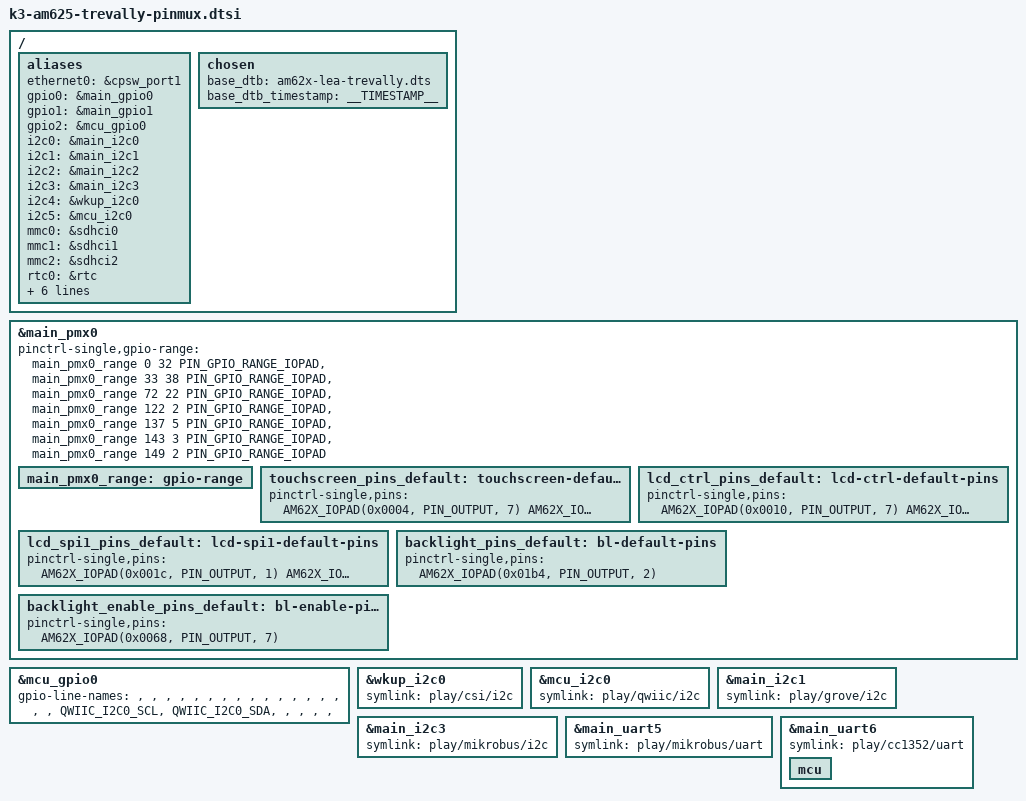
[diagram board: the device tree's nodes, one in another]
// SPDX-License-Identifier: GPL-2.0-only OR MIT

#include <dt-bindings/gpio/gpio.h>

/ {
	/* rtc1 = &wkup_rtc0; diff */
	aliases {
		ethernet0 = &cpsw_port1;
		gpio0 = &main_gpio0;
		gpio1 = &main_gpio1;
		gpio2 = &mcu_gpio0;
		i2c0 = &main_i2c0;
		i2c1 = &main_i2c1;
		i2c2 = &main_i2c2;
		i2c3 = &main_i2c3;
		i2c4 = &wkup_i2c0;
		i2c5 = &mcu_i2c0;
		mmc0 = &sdhci0;
		mmc1 = &sdhci1;
		mmc2 = &sdhci2;
		rtc0 = &rtc;
		rtc1 = &wkup_rtc0;
		serial0 = &main_uart5;
		serial1 = &main_uart6;
		serial2 = &main_uart0;
		usb0 = &usb0;
		usb1 = &usb1;
	};

	chosen {
		base_dtb = "am62x-lea-trevally.dts";
		base_dtb_timestamp = __TIMESTAMP__;
	};

};

&main_pmx0 {
	pinctrl-single,gpio-range =
		<&main_pmx0_range 0 32 PIN_GPIO_RANGE_IOPAD>,
		<&main_pmx0_range 33 38 PIN_GPIO_RANGE_IOPAD>,
		<&main_pmx0_range 72 22 PIN_GPIO_RANGE_IOPAD>,
		<&main_pmx0_range 122 2 PIN_GPIO_RANGE_IOPAD>,
		<&main_pmx0_range 137 5 PIN_GPIO_RANGE_IOPAD>,
		<&main_pmx0_range 143 3 PIN_GPIO_RANGE_IOPAD>,
		<&main_pmx0_range 149 2 PIN_GPIO_RANGE_IOPAD>;

	main_pmx0_range: gpio-range {
		#pinctrl-single,gpio-range-cells = <3>;
	};

	touchscreen_pins_default: touchscreen-default-pins {
		pinctrl-single,pins = <
			AM62X_IOPAD(0x0004, PIN_OUTPUT, 7) /* (G25) OSPI0_LBCLKO.GPIO0_1 - CTP_RST */
			AM62X_IOPAD(0x017c, PIN_INPUT, 7)  /* (AD22) RGMII2_RX_CTL.GPIO1_1 - CTP_INT */
		>;
	};

	lcd_ctrl_pins_default: lcd-ctrl-default-pins {
		pinctrl-single,pins = <
			AM62X_IOPAD(0x0010, PIN_OUTPUT, 7) /* (G24) OSPI0_D1.GPIO0_4 - TFT_SLEEP */
			AM62X_IOPAD(0x0034, PIN_OUTPUT, 7) /* (H21) OSPI0_CSn2.GPIO0_13 - LCD_RSTn */
		>;
	};

	lcd_spi1_pins_default: lcd-spi1-default-pins {
		pinctrl-single,pins = <
			AM62X_IOPAD(0x001c, PIN_OUTPUT, 1) /* (J23) OSPI0_D4.SPI1_CS0 */
			AM62X_IOPAD(0x0020, PIN_INPUT, 1)  /* (J25) OSPI0_D5.SPI1_CLK */
			AM62X_IOPAD(0x0024, PIN_OUTPUT, 1) /* (H25) OSPI0_D6.SPI1_D0 */
		>;
	};

	/* DMT049W1NTCMI-1A backlight boost (20V) PWM dimming/enable input.
	 * PILOTFISH-QUAD-v128.syscfg: EPWM1_20V0_PWM.A -> SPI0_CS0 (EHRPWM0_A) */
	backlight_pins_default: bl-default-pins {
		pinctrl-single,pins = <
			AM62X_IOPAD(0x01b4, PIN_OUTPUT, 2) /* (A13) SPI0_CS0.EHRPWM0_A */
		>;
	};

	backlight_enable_pins_default: bl-enable-pins {
		pinctrl-single,pins = <
			AM62X_IOPAD(0x0068, PIN_OUTPUT, 7) /* (R21) GPMC0_AD11.GPIO0_26 */
		>;
	};
};

&mcu_gpio0 {
	gpio-line-names = "", "", "", "",			/* 0-3 */
		"", "", "", "",					/* 4-7 */
		"", "", "", "",					/* 8-11 */
		"", "", "", "",					/* 12-15 */
		"", "QWIIC_I2C0_SCL", "QWIIC_I2C0_SDA", "",	/* 16-19 */
		"", "", "", "";					/* 20-23 */
};

&wkup_i2c0 {
	symlink = "play/csi/i2c";
};

&mcu_i2c0 {
	symlink = "play/qwiic/i2c";
};

&main_i2c1 {
	symlink = "play/grove/i2c";
};

&main_i2c3 {
	symlink = "play/mikrobus/i2c";
};

&main_uart5 {
	symlink = "play/mikrobus/uart";
};

&main_uart6 {
	symlink = "play/cc1352/uart";

	mcu {
		status = "okay";
	};
};
